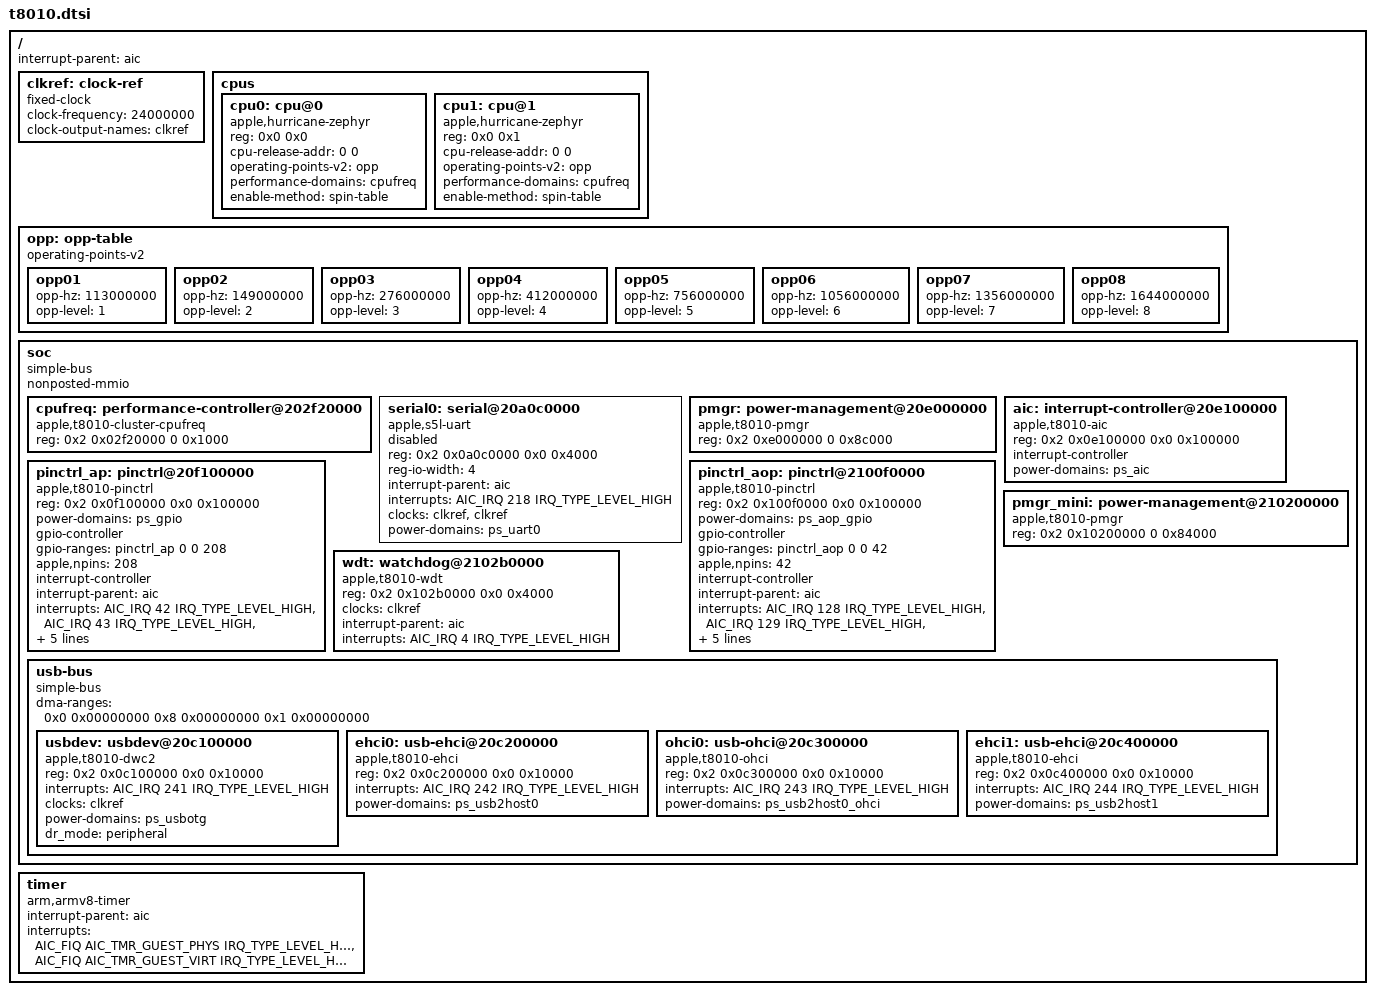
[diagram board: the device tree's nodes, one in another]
// SPDX-License-Identifier: GPL-2.0 OR MIT
/*
 * Apple T8010 "A10" SoC
 *
 * Other names: H9P, "Cayman"
 *
 * Copyright (c) 2022, Konrad Dybcio <konradybcio@kernel.org>
 */

#include <dt-bindings/gpio/gpio.h>
#include <dt-bindings/interrupt-controller/apple-aic.h>
#include <dt-bindings/interrupt-controller/irq.h>
#include <dt-bindings/pinctrl/apple.h>

/ {
	interrupt-parent = <&aic>;
	#address-cells = <2>;
	#size-cells = <2>;

	clkref: clock-ref {
		compatible = "fixed-clock";
		#clock-cells = <0>;
		clock-frequency = <24000000>;
		clock-output-names = "clkref";
	};

	cpus {
		#address-cells = <2>;
		#size-cells = <0>;

		cpu0: cpu@0 {
			compatible = "apple,hurricane-zephyr";
			reg = <0x0 0x0>; /* Variable depending on p-state, assumes E-core entry */
			cpu-release-addr = <0 0>; /* To be filled by loader */
			operating-points-v2 = <&opp>;
			performance-domains = <&cpufreq>;
			enable-method = "spin-table";
			device_type = "cpu";
		};

		cpu1: cpu@1 {
			compatible = "apple,hurricane-zephyr";
			reg = <0x0 0x1>; /* Variable depending on p-state, assumes E-core entry */
			cpu-release-addr = <0 0>; /* To be filled by loader */
			operating-points-v2 = <&opp>;
			performance-domains = <&cpufreq>;
			enable-method = "spin-table";
			device_type = "cpu";
		};
	};

	opp: opp-table {
		compatible = "operating-points-v2";

		/*
		 * Apple Fusion Architecture: Hardwired big.LITTLE switcher
		 * that use p-state transitions to switch between cores.
		 *
		 * The E-core frequencies are adjusted so performance scales
		 * linearly with reported clock speed.
		 */

		opp01 {
			opp-hz = /bits/ 64 <113000000>; /* 300 MHz, E-core */
			opp-level = <1>;
		};

		opp02 {
			opp-hz = /bits/ 64 <149000000>; /* 396 MHz, E-core */
			opp-level = <2>;
		};

		opp03 {
			opp-hz = /bits/ 64 <276000000>; /* 732 MHz, E-core */
			opp-level = <3>;
		};

		opp04 {
			opp-hz = /bits/ 64 <412000000>; /* 1092 MHz, E-core */
			opp-level = <4>;
		};

		opp05 {
			opp-hz = /bits/ 64 <756000000>;
			opp-level = <5>;
		};

		opp06 {
			opp-hz = /bits/ 64 <1056000000>;
			opp-level = <6>;
		};

		opp07 {
			opp-hz = /bits/ 64 <1356000000>;
			opp-level = <7>;
		};

		opp08 {
			opp-hz = /bits/ 64 <1644000000>;
			opp-level = <8>;
		};

		/* iPod touch 7 only go up to 1.64 GHz */
	};

	soc {
		compatible = "simple-bus";
		#address-cells = <2>;
		#size-cells = <2>;
		nonposted-mmio;
		ranges;

		cpufreq: performance-controller@202f20000 {
			compatible = "apple,t8010-cluster-cpufreq", "apple,t8103-cluster-cpufreq", "apple,cluster-cpufreq";
			reg = <0x2 0x02f20000 0 0x1000>;
			#performance-domain-cells = <0>;
		};

		serial0: serial@20a0c0000 {
			compatible = "apple,s5l-uart";
			reg = <0x2 0x0a0c0000 0x0 0x4000>;
			reg-io-width = <4>;
			interrupt-parent = <&aic>;
			interrupts = <AIC_IRQ 218 IRQ_TYPE_LEVEL_HIGH>;
			/* Use the bootloader-enabled clocks for now. */
			clocks = <&clkref>, <&clkref>;
			clock-names = "uart", "clk_uart_baud0";
			power-domains = <&ps_uart0>;
			status = "disabled";
		};

		pmgr: power-management@20e000000 {
			compatible = "apple,t8010-pmgr", "apple,pmgr", "syscon", "simple-mfd";
			#address-cells = <1>;
			#size-cells = <1>;

			reg = <0x2 0xe000000 0 0x8c000>;
		};

		aic: interrupt-controller@20e100000 {
			compatible = "apple,t8010-aic", "apple,aic";
			reg = <0x2 0x0e100000 0x0 0x100000>;
			#interrupt-cells = <3>;
			interrupt-controller;
			power-domains = <&ps_aic>;
		};

		pinctrl_ap: pinctrl@20f100000 {
			compatible = "apple,t8010-pinctrl", "apple,pinctrl";
			reg = <0x2 0x0f100000 0x0 0x100000>;
			power-domains = <&ps_gpio>;

			gpio-controller;
			#gpio-cells = <2>;
			gpio-ranges = <&pinctrl_ap 0 0 208>;
			apple,npins = <208>;

			interrupt-controller;
			#interrupt-cells = <2>;
			interrupt-parent = <&aic>;
			interrupts = <AIC_IRQ 42 IRQ_TYPE_LEVEL_HIGH>,
				     <AIC_IRQ 43 IRQ_TYPE_LEVEL_HIGH>,
				     <AIC_IRQ 44 IRQ_TYPE_LEVEL_HIGH>,
				     <AIC_IRQ 45 IRQ_TYPE_LEVEL_HIGH>,
				     <AIC_IRQ 46 IRQ_TYPE_LEVEL_HIGH>,
				     <AIC_IRQ 47 IRQ_TYPE_LEVEL_HIGH>,
				     <AIC_IRQ 48 IRQ_TYPE_LEVEL_HIGH>;
		};

		pinctrl_aop: pinctrl@2100f0000 {
			compatible = "apple,t8010-pinctrl", "apple,pinctrl";
			reg = <0x2 0x100f0000 0x0 0x100000>;
			power-domains = <&ps_aop_gpio>;

			gpio-controller;
			#gpio-cells = <2>;
			gpio-ranges = <&pinctrl_aop 0 0 42>;
			apple,npins = <42>;

			interrupt-controller;
			#interrupt-cells = <2>;
			interrupt-parent = <&aic>;
			interrupts = <AIC_IRQ 128 IRQ_TYPE_LEVEL_HIGH>,
				     <AIC_IRQ 129 IRQ_TYPE_LEVEL_HIGH>,
				     <AIC_IRQ 130 IRQ_TYPE_LEVEL_HIGH>,
				     <AIC_IRQ 131 IRQ_TYPE_LEVEL_HIGH>,
				     <AIC_IRQ 132 IRQ_TYPE_LEVEL_HIGH>,
				     <AIC_IRQ 133 IRQ_TYPE_LEVEL_HIGH>,
				     <AIC_IRQ 134 IRQ_TYPE_LEVEL_HIGH>;
		};

		pmgr_mini: power-management@210200000 {
			compatible = "apple,t8010-pmgr", "apple,pmgr", "syscon", "simple-mfd";
			#address-cells = <1>;
			#size-cells = <1>;

			reg = <0x2 0x10200000 0 0x84000>;
		};

		wdt: watchdog@2102b0000 {
			compatible = "apple,t8010-wdt", "apple,wdt";
			reg = <0x2 0x102b0000 0x0 0x4000>;
			clocks = <&clkref>;
			interrupt-parent = <&aic>;
			interrupts = <AIC_IRQ 4 IRQ_TYPE_LEVEL_HIGH>;
		};

		usb-bus {
			compatible = "simple-bus";
			#address-cells = <2>;
			#size-cells = <2>;
			dma-ranges = <0x0 0x00000000 0x8 0x00000000 0x1 0x00000000>;
			ranges;

			usbdev: usbdev@20c100000 {
				compatible = "apple,t8010-dwc2", "apple,dwc2";
				reg = <0x2 0x0c100000 0x0 0x10000>;
				interrupts = <AIC_IRQ 241 IRQ_TYPE_LEVEL_HIGH>;
				clocks = <&clkref>;
				clock-names = "otg";
				power-domains = <&ps_usbotg>;
				dr_mode = "peripheral";
			};

			ehci0: usb-ehci@20c200000 {
				compatible = "apple,t8010-ehci", "generic-ehci";
				reg = <0x2 0x0c200000 0x0 0x10000>;
				interrupts = <AIC_IRQ 242 IRQ_TYPE_LEVEL_HIGH>;
				power-domains = <&ps_usb2host0>;
			};

			ohci0: usb-ohci@20c300000 {
				compatible = "apple,t8010-ohci", "generic-ohci";
				reg = <0x2 0x0c300000 0x0 0x10000>;
				interrupts = <AIC_IRQ 243 IRQ_TYPE_LEVEL_HIGH>;
				power-domains = <&ps_usb2host0_ohci>;
			};

			ehci1: usb-ehci@20c400000 {
				compatible = "apple,t8010-ehci", "generic-ehci";
				reg = <0x2 0x0c400000 0x0 0x10000>;
				interrupts = <AIC_IRQ 244 IRQ_TYPE_LEVEL_HIGH>;
				power-domains = <&ps_usb2host1>;
			};
		};
	};

	timer {
		compatible = "arm,armv8-timer";
		interrupt-parent = <&aic>;
		interrupt-names = "phys", "virt";
		/* Note that A10 doesn't actually have a hypervisor (EL2 is not implemented). */
		interrupts = <AIC_FIQ AIC_TMR_GUEST_PHYS IRQ_TYPE_LEVEL_HIGH>,
			     <AIC_FIQ AIC_TMR_GUEST_VIRT IRQ_TYPE_LEVEL_HIGH>;
	};
};

#include "t8010-pmgr.dtsi"
